# STM32H7RSxx register map
File version: 0.2
CPU: CM7 r0p1, little endian, MPU, FPU, 4 interrupt priority bits
Registers are 32-bit, read-write, reset 0x0 unless marked. A register's access mark holds for its fields unless they carry their own. Offsets are from the block's base; [hi:lo] are bit positions; {n}, {i} and the like mark numbered series; 'fields as' and 'values as' point back to an identical list.

## OTG_HS (part 3 of 3) — OTG register block
Base 0x40040000
Same registers: OTG_FS 0x40080000
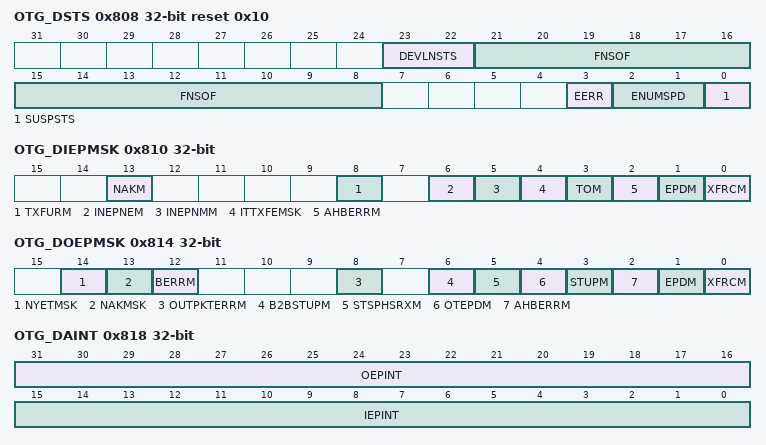
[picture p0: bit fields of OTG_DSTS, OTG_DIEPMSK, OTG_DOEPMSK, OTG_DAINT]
0x808 OTG_DSTS ro reset 0x10 — OTG device status register
  [23:22] DEVLNSTS — Device line status Indicates the current logic level USB data lines. Bit [23]: Logic level of D+ Bit [22]: Logic level of D-
  [21:8] FNSOF — Frame number of the received SOF
  [3] EERR — Erratic error The core sets this bit to report any erratic errors. Due to erratic errors, the OTG_HS controller goes into suspended state and an interrupt is generated to the application with Early suspend bit of the OTG_GINTSTS register (ESUSP bit in OTG_GINTSTS). If the early suspend is asserted due to an erratic error, the application can only perform a soft disconnect recover.
  [2:1] ENUMSPD — Enumerated speed Indicates the speed at which the OTG_HS controller has come up after speed detection through a chirp sequence. Others: reserved
    0=High Speed; 1=Full Speed
  [0] SUSPSTS — Suspend status In device mode, this bit is set as long as a suspend condition is detected on the USB. The core enters the suspended state when there is no activity on the USB data lines for a period of 3 ms. The core comes out of the suspend: When there is an activity on the USB data lines When the application writes to the remote wakeup signaling bit in the OTG_DCTL register (RWUSIG bit in OTG_DCTL).
0x810 OTG_DIEPMSK — OTG device IN endpoint common interrupt mask register
  [all] fields
    0=Masked interrupt; 1=Unmasked interrupt
  [13] NAKM — NAK interrupt mask
  [8] TXFURM — FIFO underrun mask
  [6] INEPNEM — IN endpoint NAK effective mask
  [5] INEPNMM — IN token received with EP mismatch mask
  [4] ITTXFEMSK — IN token received when Tx FIFO empty mask
  [3] TOM — Timeout condition mask (Non-isochronous endpoints)
  [2] AHBERRM — AHB error mask
  [1] EPDM — Endpoint disabled interrupt mask
  [0] XFRCM — Transfer completed interrupt mask
0x814 OTG_DOEPMSK — OTG device OUT endpoint common interrupt mask register
  [all] fields
    0=Masked interrupt; 1=Unmasked interrupt
  [14] NYETMSK — NYET interrupt mask
  [13] NAKMSK — NAK interrupt mask
  [12] BERRM — Babble error interrupt mask
  [8] OUTPKTERRM — Out packet error mask
  [6] B2BSTUPM — Back-to-back SETUP packets received mask Applies to control OUT endpoints only.
  [5] STSPHSRXM — Status phase received for control write mask
  [4] OTEPDM — OUT token received when endpoint disabled mask. Applies to control OUT endpoints only.
  [3] STUPM — STUPM: SETUP phase done mask. Applies to control endpoints only.
  [2] AHBERRM — AHB error mask
  [1] EPDM — Endpoint disabled interrupt mask
  [0] XFRCM — Transfer completed interrupt mask
0x818 OTG_DAINT ro — OTG device all endpoints interrupt register
  [31:16] OEPINT — OUT endpoint interrupt bits One bit per OUT endpoint: Bit 16 for OUT endpoint 0, bit 19 for OUT endpoint 3.
  [15:0] IEPINT — IN endpoint interrupt bits One bit per IN endpoint: Bit 0 for IN endpoint 0, bit 3 for endpoint 3.
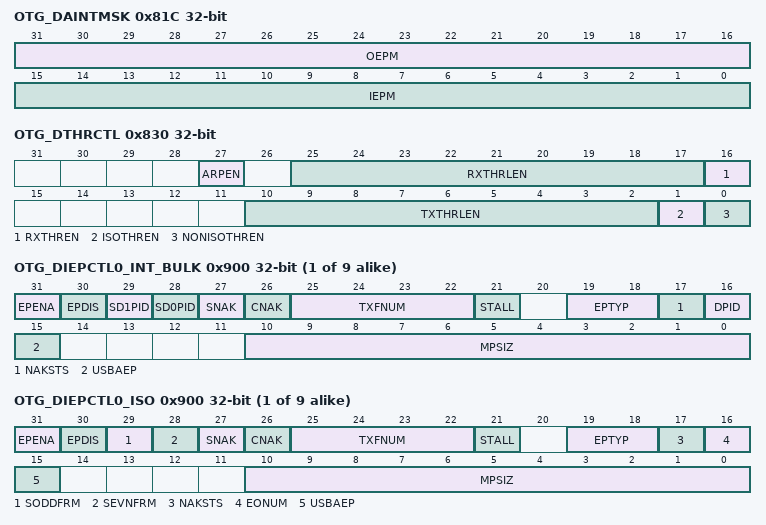
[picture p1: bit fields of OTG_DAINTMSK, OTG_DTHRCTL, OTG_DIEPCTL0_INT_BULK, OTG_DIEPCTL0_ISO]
0x81C OTG_DAINTMSK — OTG all endpoints interrupt mask register
  [31:16] OEPM — OUT EP interrupt mask bits One per OUT endpoint: Bit 16 for OUT EP 0, bit 19 for OUT EP 3
    0=Masked interrupt; 1=Unmasked interrupt
  [15:0] IEPM — IN EP interrupt mask bits One bit per IN endpoint: Bit 0 for IN EP 0, bit 3 for IN EP 3
    0=Masked interrupt; 1=Unmasked interrupt
0x830 OTG_DTHRCTL — OTG device threshold control register
  [27] ARPEN — Arbiter parking enable This bit controls internal DMA arbiter parking for IN endpoints. When thresholding is enabled and this bit is set to one, then the arbiter parks on the IN endpoint for which there is a token received on the USB. This is done to avoid getting into underrun conditions. By default parking is enabled.
  [25:17] RXTHRLEN — Receive threshold length This field specifies the receive thresholding size in 32-bit words. This field also specifies the amount of data received on the USB before the core can start transmitting on the AHB. The threshold length has to be at least eight 32-bit words. The recommended value for RXTHRLEN is to be the same as the programmed AHB burst length (HBSTLEN bit in OTG_GAHBCFG).
  [16] RXTHREN — Receive threshold enable When this bit is set, the core enables thresholding in the receive direction.
  [10:2] TXTHRLEN — Transmit threshold length This field specifies the transmit thresholding size in 32-bit words. This field specifies the amount of data in bytes to be in the corresponding endpoint transmit FIFO, before the core can start transmitting on the USB. The threshold length has to be at least eight 32-bit words. This field controls both isochronous and nonisochronous IN endpoint thresholds. The recommended value for TXTHRLEN is to be the same as the programmed AHB burst length (HBSTLEN bit in OTG_GAHBCFG).
  [1] ISOTHREN — ISO IN endpoint threshold enable When this bit is set, the core enables thresholding for isochronous IN endpoints.
  [0] NONISOTHREN — Nonisochronous IN endpoints threshold enable When this bit is set, the core enables thresholding for nonisochronous IN endpoints.
0x834 OTG_DIEPEMPMSK — OTG device IN endpoint FIFO empty interrupt mask register
  [15:0] INEPTXFEM — IN EP Tx FIFO empty interrupt mask bits These bits act as mask bits for OTG_DIEPINTx. TXFE interrupt one bit per IN endpoint: Bit 0 for IN endpoint 0, bit 3 for IN endpoint 3
    0=Masked interrupt; 1=Unmasked interrupt
{0x900+0x20*i} OTG_DIEPCTL{i}_INT_BULK access per field (i=0..8) — OTG device IN endpoint {i} control register
  [31] EPENA rw — Endpoint enable The application sets this bit to start transmitting data on an endpoint. The core clears this bit before setting any of the following interrupts on this endpoint: SETUP phase done Endpoint disabled Transfer completed
  [30] EPDIS rw — Endpoint disable The application sets this bit to stop transmitting/receiving data on an endpoint, even before the transfer for that endpoint is complete. The application must wait for the endpoint disabled interrupt before treating the endpoint as disabled. The core clears this bit before setting the endpoint disabled interrupt. The application must set this bit only if endpoint enable is already set for this endpoint.
  [29] SD1PID wo — Set DATA1 PID Writing to this field sets the endpoint data PID (DPID) field in this register to DATA1.
  [28] SD0PID wo — Set DATA0 PID Applies to interrupt/bulk IN endpoints only. Writing to this field sets the endpoint data PID (DPID) field in this register to DATA0.
  [27] SNAK wo — Set NAK A write to this bit sets the NAK bit for the endpoint. Using this bit, the application can control the transmission of NAK handshakes on an endpoint. The core can also set this bit for OUT endpoints on a transfer completed interrupt, or after a SETUP is received on the endpoint.
  [26] CNAK wo — Clear NAK A write to this bit clears the NAK bit for the endpoint.
  [25:22] TXFNUM rw — Tx FIFO number These bits specify the FIFO number associated with this endpoint. Each active IN endpoint must be programmed to a separate FIFO number. This field is valid only for IN endpoints.
  [21] STALL rw — STALL handshake Applies to non-control, non-isochronous IN endpoints only (access type is rw). The application sets this bit to stall all tokens from the USB host to this endpoint. If a NAK bit, Global IN NAK, or Global OUT NAK is set along with this bit, the STALL bit takes priority. Only the application can clear this bit, never the core.
  [19:18] EPTYP rw — Endpoint type This is the transfer type supported by this logical endpoint.
    0=Control; 1=Isochronous; 2=Bulk; 3=Interrupt
  [17] NAKSTS ro — NAK status It indicates the following: When either the application or the core sets this bit: For non-isochronous IN endpoints: The core stops transmitting any data on an IN endpoint, even if there are data available in the Tx FIFO. For isochronous IN endpoints: The core sends out a zero-length data packet, even if there are data available in the Tx FIFO. Irrespective of this bit’s setting, the core always responds to SETUP data packets with an ACK handshake.
    0=The core is transmitting non-NAK handshakes based on the FIFO status; 1=The core is transmitting NAK handshakes on this endpoint
  [16] DPID ro — Endpoint data PID Applies to interrupt/bulk IN endpoints only. Contains the PID of the packet to be received or transmitted on this endpoint. The application must program the PID of the first packet to be received or transmitted on this endpoint, after the endpoint is activated. The application uses the SD0PID and SD1PID register fields to program either DATA0 or DATA1 PID.
    0=DATA0; 1=DATA1
  [15] USBAEP rw — USB active endpoint Indicates whether this endpoint is active in the current configuration and interface. The core clears this bit for all endpoints (other than EP 0) after detecting a USB reset. After receiving the SetConfiguration and SetInterface commands, the application must program endpoint registers accordingly and set this bit.
  [10:0] MPSIZ rw — Maximum packet size The application must program this field with the maximum packet size for the current logical endpoint. This value is in bytes.
{0x900+0x20*i} OTG_DIEPCTL{i}_ISO access per field (alternate view of OTG_DIEPCTL{i}_INT_BULK) (i=0..8) — OTG device IN endpoint {i} control register
  [31] EPENA rw — Endpoint enable The application sets this bit to start transmitting data on an endpoint. The core clears this bit before setting any of the following interrupts on this endpoint: SETUP phase done Endpoint disabled Transfer completed
  [30] EPDIS rw — Endpoint disable The application sets this bit to stop transmitting/receiving data on an endpoint, even before the transfer for that endpoint is complete. The application must wait for the endpoint disabled interrupt before treating the endpoint as disabled. The core clears this bit before setting the endpoint disabled interrupt. The application must set this bit only if endpoint enable is already set for this endpoint.
  [29] SODDFRM wo — Set odd frame Applies to isochronous IN and OUT endpoints only. Writing to this field sets the Even/Odd frame (EONUM) field to odd frame.
  [28] SEVNFRM wo — Set even frame Applies to isochronous IN endpoints only. Writing to this field sets the Even/Odd frame (EONUM) field to even frame.
  [27] SNAK wo — Set NAK A write to this bit sets the NAK bit for the endpoint. Using this bit, the application can control the transmission of NAK handshakes on an endpoint. The core can also set this bit for OUT endpoints on a transfer completed interrupt, or after a SETUP is received on the endpoint.
  [26] CNAK wo — Clear NAK A write to this bit clears the NAK bit for the endpoint.
  [25:22] TXFNUM rw — Tx FIFO number These bits specify the FIFO number associated with this endpoint. Each active IN endpoint must be programmed to a separate FIFO number. This field is valid only for IN endpoints.
  [21] STALL rw — STALL handshake Applies to non-control, non-isochronous IN endpoints only (access type is rw). The application sets this bit to stall all tokens from the USB host to this endpoint. If a NAK bit, Global IN NAK, or Global OUT NAK is set along with this bit, the STALL bit takes priority. Only the application can clear this bit, never the core.
  [19:18] EPTYP rw — Endpoint type This is the transfer type supported by this logical endpoint.
    0=Control; 1=Isochronous; 2=Bulk; 3=Interrupt
  [17] NAKSTS ro — NAK status It indicates the following: When either the application or the core sets this bit: For non-isochronous IN endpoints: The core stops transmitting any data on an IN endpoint, even if there are data available in the Tx FIFO. For isochronous IN endpoints: The core sends out a zero-length data packet, even if there are data available in the Tx FIFO. Irrespective of this bit’s setting, the core always responds to SETUP data packets with an ACK handshake.
    values as OTG_DIEPCTL0_INT_BULK.NAKSTS
  [16] EONUM ro — Even/odd frame Applies to isochronous IN endpoints only. Indicates the frame number in which the core transmits/receives isochronous data for this endpoint. The application must program the even/odd frame number in which it intends to transmit/receive isochronous data for this endpoint using the SEVNFRM and SODDFRM fields in this register.
    0=Even frame; 1=Odd frame
  [15] USBAEP rw — USB active endpoint Indicates whether this endpoint is active in the current configuration and interface. The core clears this bit for all endpoints (other than EP 0) after detecting a USB reset. After receiving the SetConfiguration and SetInterface commands, the application must program endpoint registers accordingly and set this bit.
  [10:0] MPSIZ rw — Maximum packet size The application must program this field with the maximum packet size for the current logical endpoint. This value is in bytes.
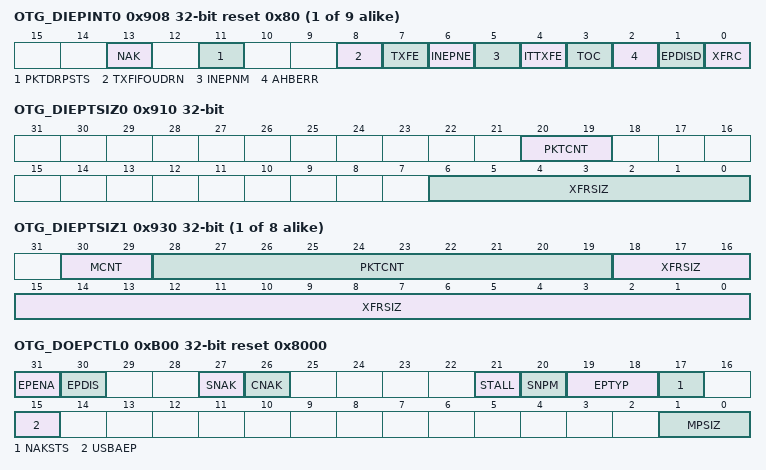
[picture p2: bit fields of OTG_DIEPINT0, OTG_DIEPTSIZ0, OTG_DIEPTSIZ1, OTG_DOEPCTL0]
{0x908+0x20*i} OTG_DIEPINT{i} access per field reset 0x80 (i=0..8) — OTG device IN endpoint {i} interrupt register
  [13] NAK rw — NAK input The core generates this interrupt when a NAK is transmitted or received by the device. In case of isochronous IN endpoints the interrupt gets generated when a zero length packet is transmitted due to unavailability of data in the Tx FIFO.
  [11] PKTDRPSTS rw — Packet dropped status This bit indicates to the application that an ISOC OUT packet has been dropped. This bit does not have an associated mask bit and does not generate an interrupt.
  [8] TXFIFOUDRN rw — Transmit Fifo Underrun (TxfifoUndrn) The core generates this interrupt when it detects a transmit FIFO underrun condition for this endpoint. Dependency: This interrupt is valid only when Thresholding is enabled
  [7] TXFE ro — Transmit FIFO empty This interrupt is asserted when the Tx FIFO for this endpoint is either half or completely empty. The half or completely empty status is determined by the Tx FIFO Empty Level bit in the OTG_GAHBCFG register (TXFELVL bit in OTG_GAHBCFG).
  [6] INEPNE rw — IN endpoint NAK effective This bit can be cleared when the application clears the IN endpoint NAK by writing to the CNAK bit in OTG_DIEPCTLx. This interrupt indicates that the core has sampled the NAK bit set (either by the application or by the core). The interrupt indicates that the IN endpoint NAK bit set by the application has taken effect in the core. This interrupt does not guarantee that a NAK handshake is sent on the USB. A STALL bit takes priority over a NAK bit.
  [5] INEPNM rw — IN token received with EP mismatch Indicates that the data in the top of the non-periodic TxFIFO belongs to an endpoint other than the one for which the IN token was received. This interrupt is asserted on the endpoint for which the IN token was received.
  [4] ITTXFE rw — IN token received when Tx FIFO is empty Indicates that an IN token was received when the associated Tx FIFO (periodic/non-periodic) was empty. This interrupt is asserted on the endpoint for which the IN token was received.
  [3] TOC rw — Timeout condition Indicates that the core has detected a timeout condition on the USB for the last IN token on this endpoint.
  [2] AHBERR rw — AHB error This is generated only in internal DMA mode when there is an AHB error during an AHB read/write. The application can read the corresponding endpoint DMA address register to get the error address.
  [1] EPDISD rw — Endpoint disabled interrupt This bit indicates that the endpoint is disabled per the application’s request.
  [0] XFRC rw — Transfer completed interrupt This field indicates that the programmed transfer is complete on the AHB as well as on the USB, for this endpoint.
0x910 OTG_DIEPTSIZ0 — OTG device IN endpoint 0 transfer size register
  [20:19] PKTCNT — Packet count Indicates the total number of USB packets that constitute the transfer size amount of data for endpoint 0. This field is decremented every time a packet (maximum size or short packet) is read from the Tx FIFO.
  [6:0] XFRSIZ — Transfer size Indicates the transfer size in bytes for endpoint 0. The core interrupts the application only after it has exhausted the transfer size amount of data. The transfer size can be set to the maximum packet size of the endpoint, to be interrupted at the end of each packet. The core decrements this field every time a packet from the external memory is written to the Tx FIFO.
{0x914+0x20*i} OTG_DIEPDMA{i} (i=0..8) — OTG device IN endpoint {i} DMA address register
  [31:0] DMAADDR — DMA Address This field holds the start address in the external memory from which the data for the endpoint must be fetched. This register is incremented on every AHB transaction.
{0x918+0x20*i} OTG_DTXFSTS{i} ro reset 0x200 (i=0..8) — OTG device IN endpoint transmit FIFO status register
  [15:0] INEPTFSAV — IN endpoint Tx FIFO space available Indicates the amount of free space available in the endpoint Tx FIFO. Values are in terms of 32-bit words: 0xn: n words available Others: Reserved
    0=Endpoint Tx FIFO is full; 1=1 word available; 2=2 words available
{0x910+0x20*i} OTG_DIEPTSIZ{i} (i=1..8) — OTG device IN endpoint {i} transfer size register
  [30:29] MCNT — Multi count For periodic IN endpoints, this field indicates the number of packets that must be transmitted per frame on the USB. The core uses this field to calculate the data PID for isochronous IN endpoints.
    1=1 packet; 2=2 packets; 3=3 packets
  [28:19] PKTCNT — Packet count Indicates the total number of USB packets that constitute the transfer size amount of data for this endpoint. This field is decremented every time a packet (maximum size or short packet) is read from the Tx FIFO.
  [18:0] XFRSIZ — Transfer size This field contains the transfer size in bytes for the current endpoint. The core only interrupts the application after it has exhausted the transfer size amount of data. The transfer size can be set to the maximum packet size of the endpoint, to be interrupted at the end of each packet. The core decrements this field every time a packet from the external memory is written to the Tx FIFO.
0xB00 OTG_DOEPCTL0 access per field reset 0x8000 — OTG device control OUT endpoint 0 control register
  [31] EPENA wo — Endpoint enable The application sets this bit to start transmitting data on endpoint 0. The core clears this bit before setting any of the following interrupts on this endpoint: SETUP phase done Endpoint disabled Transfer completed
  [30] EPDIS ro — Endpoint disable The application cannot disable control OUT endpoint 0.
  [27] SNAK wo — Set NAK A write to this bit sets the NAK bit for the endpoint. Using this bit, the application can control the transmission of NAK handshakes on an endpoint. The core can also set this bit on a transfer completed interrupt, or after a SETUP is received on the endpoint.
  [26] CNAK wo — Clear NAK A write to this bit clears the NAK bit for the endpoint.
  [21] STALL rw — STALL handshake The application can only set this bit, and the core clears it, when a SETUP token is received for this endpoint. If a NAK bit or Global OUT NAK is set along with this bit, the STALL bit takes priority. Irrespective of this bit’s setting, the core always responds to SETUP data packets with an ACK handshake.
  [20] SNPM rw — Snoop mode This bit configures the endpoint to Snoop mode. In Snoop mode, the core does not check the correctness of OUT packets before transferring them to application memory.
  [19:18] EPTYP ro — Endpoint type Hardcoded to 00 for control.
  [17] NAKSTS ro — NAK status Indicates the following: When either the application or the core sets this bit, the core stops receiving data, even if there is space in the Rx FIFO to accommodate the incoming packet. Irrespective of this bit’s setting, the core always responds to SETUP data packets with an ACK handshake.
    values as OTG_DIEPCTL0_INT_BULK.NAKSTS
  [15] USBAEP ro — USB active endpoint This bit is always set to 1, indicating that a control endpoint 0 is always active in all configurations and interfaces.
  [1:0] MPSIZ ro — Maximum packet size The maximum packet size for control OUT endpoint 0 is the same as what is programmed in control IN endpoint 0.
    0=64 bytes; 1=32 bytes; 2=16 bytes; 3=8 bytes
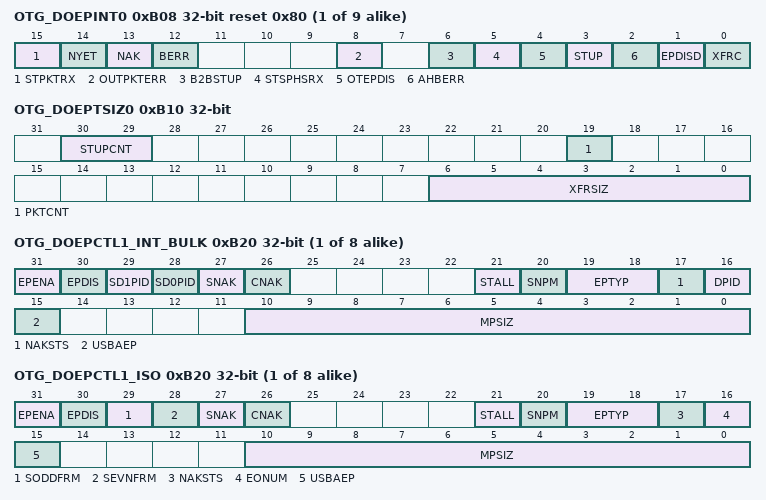
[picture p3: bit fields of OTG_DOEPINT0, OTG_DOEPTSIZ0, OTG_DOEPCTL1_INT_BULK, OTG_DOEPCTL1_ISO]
{0xB08+0x20*i} OTG_DOEPINT{i} reset 0x80 (i=0..8) — OTG device OUT endpoint {i} interrupt register
  [15] STPKTRX — Setup packet received Applicable for control OUT endpoints in only in the Buffer DMA Mode. Set by the OTG_HS, this bit indicates that this buffer holds 8 bytes of setup data. There is only one setup packet per buffer. On receiving a setup packet, the OTG_HS closes the buffer and disables the corresponding endpoint after SETUP_COMPLETE status is seen in the Rx FIFO. OTG_HS puts a SETUP_COMPLETE status into the Rx FIFO when it sees the first IN or OUT token after the SETUP packet for that particular endpoint. The application must then re-enable the endpoint to receive any OUT data for the control transfer and reprogram the buffer start address. Because of the above behavior, OTG_HS can receive any number of back to back setup packets and one buffer for every setup packet is used.
  [14] NYET — NYET interrupt This interrupt is generated when a NYET response is transmitted for a non isochronous OUT endpoint.
  [13] NAK — NAK input The core generates this interrupt when a NAK is transmitted or received by the device. In case of isochronous IN endpoints the interrupt gets generated when a zero length packet is transmitted due to unavailability of data in the Tx FIFO.
  [12] BERR — Babble error interrupt The core generates this interrupt when babble is received for the endpoint.
  [8] OUTPKTERR — OUT packet error This interrupt is asserted when the core detects an overflow or a CRC error for an OUT packet. This interrupt is valid only when thresholding is enabled.
  [6] B2BSTUP — Back-to-back SETUP packets received Applies to control OUT endpoint only. This bit indicates that the core has received more than three back-to-back SETUP packets for this particular endpoint.
  [5] STSPHSRX — Status phase received for control write This interrupt is valid only for control OUT endpoints. This interrupt is generated only after OTG_HS has transferred all the data that the host has sent during the data phase of a control write transfer, to the system memory buffer. The interrupt indicates to the application that the host has switched from data phase to the status phase of a control write transfer. The application can use this interrupt to ACK or STALL the status phase, after it has decoded the data phase.
  [4] OTEPDIS — OUT token received when endpoint disabled Applies only to control OUT endpoints. Indicates that an OUT token was received when the endpoint was not yet enabled. This interrupt is asserted on the endpoint for which the OUT token was received.
  [3] STUP — SETUP phase done Applies to control OUT endpoint only.Indicates that the SETUP phase for the control endpoint is complete and no more back-to-back SETUP packets were received for the current control transfer. On this interrupt, the application can decode the received SETUP data packet.
  [2] AHBERR — AHB error This is generated only in internal DMA mode when there is an AHB error during an AHB read/write. The application can read the corresponding endpoint DMA address register to get the error address.
  [1] EPDISD — Endpoint disabled interrupt This bit indicates that the endpoint is disabled per the application’s request.
  [0] XFRC — Transfer completed interrupt This field indicates that the programmed transfer is complete on the AHB as well as on the USB, for this endpoint.
0xB10 OTG_DOEPTSIZ0 — OTG device OUT endpoint 0 transfer size register
  [30:29] STUPCNT — SETUP packet count This field specifies the number of back-to-back SETUP data packets the endpoint can receive.
    1=1 packet; 2=2 packets; 3=3 packets
  [19] PKTCNT — Packet count This field is decremented to zero after a packet is written into the Rx FIFO.
  [6:0] XFRSIZ — Transfer size Indicates the transfer size in bytes for endpoint 0. The core interrupts the application only after it has exhausted the transfer size amount of data. The transfer size can be set to the maximum packet size of the endpoint, to be interrupted at the end of each packet. The core decrements this field every time a packet is read from the Rx FIFO and written to the external memory.
{0xB14+0x20*i} OTG_DOEPDMA{i} (i=0..8) — OTG device OUT endpoint {i} DMA address register
  fields as OTG_DIEPDMA0
{0xB00+0x20*i} OTG_DOEPCTL{i}_INT_BULK access per field (i=1..8) — OTG device OUT endpoint {i} control register
  [31] EPENA rw — Endpoint enable Applies to IN and OUT endpoints. The application sets this bit to start transmitting data on an endpoint. The core clears this bit before setting any of the following interrupts on this endpoint: SETUP phase done Endpoint disabled Transfer completed
  [30] EPDIS rw — Endpoint disable The application sets this bit to stop transmitting/receiving data on an endpoint, even before the transfer for that endpoint is complete. The application must wait for the endpoint disabled interrupt before treating the endpoint as disabled. The core clears this bit before setting the endpoint disabled interrupt. The application must set this bit only if endpoint enable is already set for this endpoint.
  [29] SD1PID wo — Set DATA1 PID Writing to this field sets the endpoint data PID (DPID) field in this register to DATA1.
  [28] SD0PID wo — Set DATA0 PID Applies to interrupt/bulk OUT endpoints only. Writing to this field sets the endpoint data PID (DPID) field in this register to DATA0.
  [27] SNAK wo — Set NAK A write to this bit sets the NAK bit for the endpoint. Using this bit, the application can control the transmission of NAK handshakes on an endpoint. The core can also set this bit for OUT endpoints on a transfer completed interrupt, or after a SETUP is received on the endpoint.
  [26] CNAK wo — Clear NAK A write to this bit clears the NAK bit for the endpoint.
  [21] STALL rw — STALL handshake Applies to non-control, non-isochronous OUT endpoints only (access type is rw). The application sets this bit to stall all tokens from the USB host to this endpoint. If a NAK bit, Global IN NAK, or Global OUT NAK is set along with this bit, the STALL bit takes priority. Only the application can clear this bit, never the core. Applies to control endpoints only (access type is rs). The application can only set this bit, and the core clears it, when a SETUP token is received for this endpoint. If a NAK bit, Global IN NAK, or Global OUT NAK is set along with this bit, the STALL bit takes priority. Irrespective of this bit’s setting, the core always responds to SETUP data packets with an ACK handshake.
  [20] SNPM rw — Snoop mode This bit configures the endpoint to Snoop mode. In Snoop mode, the core does not check the correctness of OUT packets before transferring them to application memory.
  [19:18] EPTYP rw — Endpoint type This is the transfer type supported by this logical endpoint.
    0=Control; 1=Isochronous; 2=Bulk; 3=Interrupt
  [17] NAKSTS ro — NAK status Indicates the following: When either the application or the core sets this bit: The core stops receiving any data on an OUT endpoint, even if there is space in the Rx FIFO to accommodate the incoming packet. Irrespective of this bit’s setting, the core always responds to SETUP data packets with an ACK handshake.
    values as OTG_DIEPCTL0_INT_BULK.NAKSTS
  [16] DPID ro — Endpoint data PID Applies to interrupt/bulk OUT endpoints only. Contains the PID of the packet to be received or transmitted on this endpoint. The application must program the PID of the first packet to be received or transmitted on this endpoint, after the endpoint is activated. The application uses the SD0PID and SD1PID register fields to program either DATA0 or DATA1 PID.
    0=DATA0; 1=DATA1
  [15] USBAEP rw — USB active endpoint Indicates whether this endpoint is active in the current configuration and interface. The core clears this bit for all endpoints (other than EP 0) after detecting a USB reset. After receiving the SetConfiguration and SetInterface commands, the application must program endpoint registers accordingly and set this bit.
  [10:0] MPSIZ rw — Maximum packet size The application must program this field with the maximum packet size for the current logical endpoint. This value is in bytes.
{0xB00+0x20*i} OTG_DOEPCTL{i}_ISO access per field (alternate view of OTG_DOEPCTL{i}_INT_BULK) (i=1..8) — OTG device OUT endpoint {i} control register
  [31] EPENA rw — Endpoint enable Applies to IN and OUT endpoints. The application sets this bit to start transmitting data on an endpoint. The core clears this bit before setting any of the following interrupts on this endpoint: SETUP phase done Endpoint disabled Transfer completed
  [30] EPDIS rw — Endpoint disable The application sets this bit to stop transmitting/receiving data on an endpoint, even before the transfer for that endpoint is complete. The application must wait for the endpoint disabled interrupt before treating the endpoint as disabled. The core clears this bit before setting the endpoint disabled interrupt. The application must set this bit only if endpoint enable is already set for this endpoint.
  [29] SODDFRM wo — Set odd frame Applies to isochronous IN and OUT endpoints only. Writing to this field sets the Even/Odd frame (EONUM) field to odd frame.
  [28] SEVNFRM wo — Set even frame Applies to isochronous OUT endpoints only. Writing to this field sets the Even/Odd frame (EONUM) field to even frame.
  [27] SNAK wo — Set NAK A write to this bit sets the NAK bit for the endpoint. Using this bit, the application can control the transmission of NAK handshakes on an endpoint. The core can also set this bit for OUT endpoints on a transfer completed interrupt, or after a SETUP is received on the endpoint.
  [26] CNAK wo — Clear NAK A write to this bit clears the NAK bit for the endpoint.
  [21] STALL rw — STALL handshake Applies to non-control, non-isochronous OUT endpoints only (access type is rw). The application sets this bit to stall all tokens from the USB host to this endpoint. If a NAK bit, Global IN NAK, or Global OUT NAK is set along with this bit, the STALL bit takes priority. Only the application can clear this bit, never the core. Applies to control endpoints only (access type is rs). The application can only set this bit, and the core clears it, when a SETUP token is received for this endpoint. If a NAK bit, Global IN NAK, or Global OUT NAK is set along with this bit, the STALL bit takes priority. Irrespective of this bit’s setting, the core always responds to SETUP data packets with an ACK handshake.
  [20] SNPM rw — Snoop mode This bit configures the endpoint to Snoop mode. In Snoop mode, the core does not check the correctness of OUT packets before transferring them to application memory.
  [19:18] EPTYP rw — Endpoint type This is the transfer type supported by this logical endpoint.
    0=Control; 1=Isochronous; 2=Bulk; 3=Interrupt
  [17] NAKSTS ro — NAK status Indicates the following: When either the application or the core sets this bit: The core stops receiving any data on an OUT endpoint, even if there is space in the Rx FIFO to accommodate the incoming packet. Irrespective of this bit’s setting, the core always responds to SETUP data packets with an ACK handshake.
    values as OTG_DIEPCTL0_INT_BULK.NAKSTS
  [16] EONUM ro — Even/odd frame Applies to isochronous OUT endpoints only. Indicates the frame number in which the core transmits/receives isochronous data for this endpoint. The application must program the even/odd frame number in which it intends to transmit/receive isochronous data for this endpoint using the SEVNFRM and SODDFRM fields in this register.
    0=Even frame; 1=Odd frame
  [15] USBAEP rw — USB active endpoint Indicates whether this endpoint is active in the current configuration and interface. The core clears this bit for all endpoints (other than EP 0) after detecting a USB reset. After receiving the SetConfiguration and SetInterface commands, the application must program endpoint registers accordingly and set this bit.
  [10:0] MPSIZ rw — Maximum packet size The application must program this field with the maximum packet size for the current logical endpoint. This value is in bytes.
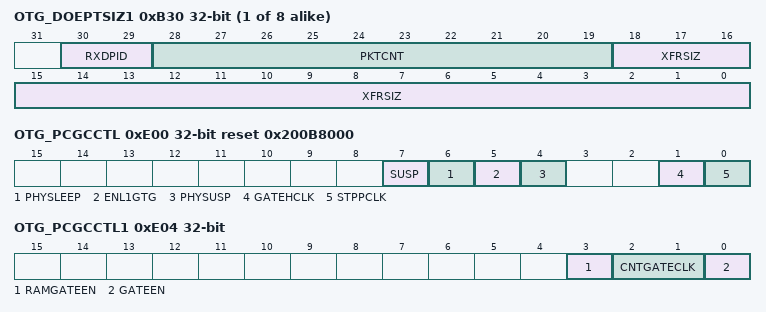
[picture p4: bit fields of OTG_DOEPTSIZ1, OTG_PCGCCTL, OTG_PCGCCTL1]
{0xB10+0x20*i} OTG_DOEPTSIZ{i} (i=1..8) — OTG device OUT endpoint {i} transfer size register
  [30:29] RXDPID — Received data PID This is the data PID received in the last packet for this endpoint. STUPCNT[1:0]: SETUP packet count This field specifies the number of back-to-back SETUP data packets the endpoint can receive.
    0=B_0x0_ISOCHRONOUS_OUT_ENDPOINTS (DATA0); 1=B_0x1_ISOCHRONOUS_OUT_ENDPOINTS (DATA2); 2=B_0x2_ISOCHRONOUS_OUT_ENDPOINTS (DATA1); 3=B_0x3_ISOCHRONOUS_OUT_ENDPOINTS (MDATA); 1=B_0x1_CONTROL_OUT_ENDPOINTS (1 packet); 2=B_0x2_CONTROL_OUT_ENDPOINTS (2 packets); 3=B_0x3_CONTROL_OUT_ENDPOINTS (3 packets)
  [28:19] PKTCNT — Packet count Indicates the total number of USB packets that constitute the transfer size amount of data for this endpoint. This field is decremented every time a packet (maximum size or short packet) is written to the Rx FIFO.
  [18:0] XFRSIZ — Transfer size This field contains the transfer size in bytes for the current endpoint. The core only interrupts the application after it has exhausted the transfer size amount of data. The transfer size can be set to the maximum packet size of the endpoint, to be interrupted at the end of each packet. The core decrements this field every time a packet is read from the Rx FIFO and written to the external memory.
0xE00 OTG_PCGCCTL access per field reset 0x200B8000 — OTG power and clock gating control register
  [7] SUSP ro — Deep Sleep This bit indicates that the PHY is in Deep Sleep when in L1 state.
  [6] PHYSLEEP ro — PHY in Sleep This bit indicates that the PHY is in the Sleep state.
  [5] ENL1GTG rw — Enable sleep clock gating When this bit is set, core internal clock gating is enabled in Sleep state if the core cannot assert utmi_l1_suspend_n. When this bit is not set, the PHY clock is not gated in Sleep state.
  [4] PHYSUSP ro — PHY suspended Indicates that the PHY has been suspended. This bit is updated once the PHY is suspended after the application has set the STPPCLK bit.
  [1] GATEHCLK rw — Gate HCLK The application sets this bit to gate HCLK to modules other than the AHB Slave and Master and wakeup logic when the USB is suspended or the session is not valid. The application clears this bit when the USB is resumed or a new session starts.
  [0] STPPCLK rw — Stop PHY clock The application sets this bit to stop the PHY clock when the USB is suspended, the session is not valid, or the device is disconnected. The application clears this bit when the USB is resumed or a new session starts.
0xE04 OTG_PCGCCTL1 — OTG power and clock gating control register 1
  [3] RAMGATEEN — Enable RAM clock gating Enable gating of the FIFO RAM.
  [2:1] CNTGATECLK — Counter for clock gating Indicates to the controller how many PHY Clock cycles and AHB Clock cycles of 'IDLE' (no activity) the controller waits for before Gating the respective PHY and AHB clocks internal to the controller.
    0=64 clocks; 1=128 clocks
  [0] GATEEN — Enable active clock gating The application programs GATEEN to enable Active Clock Gating feature for the PHY and AHB clocks.
